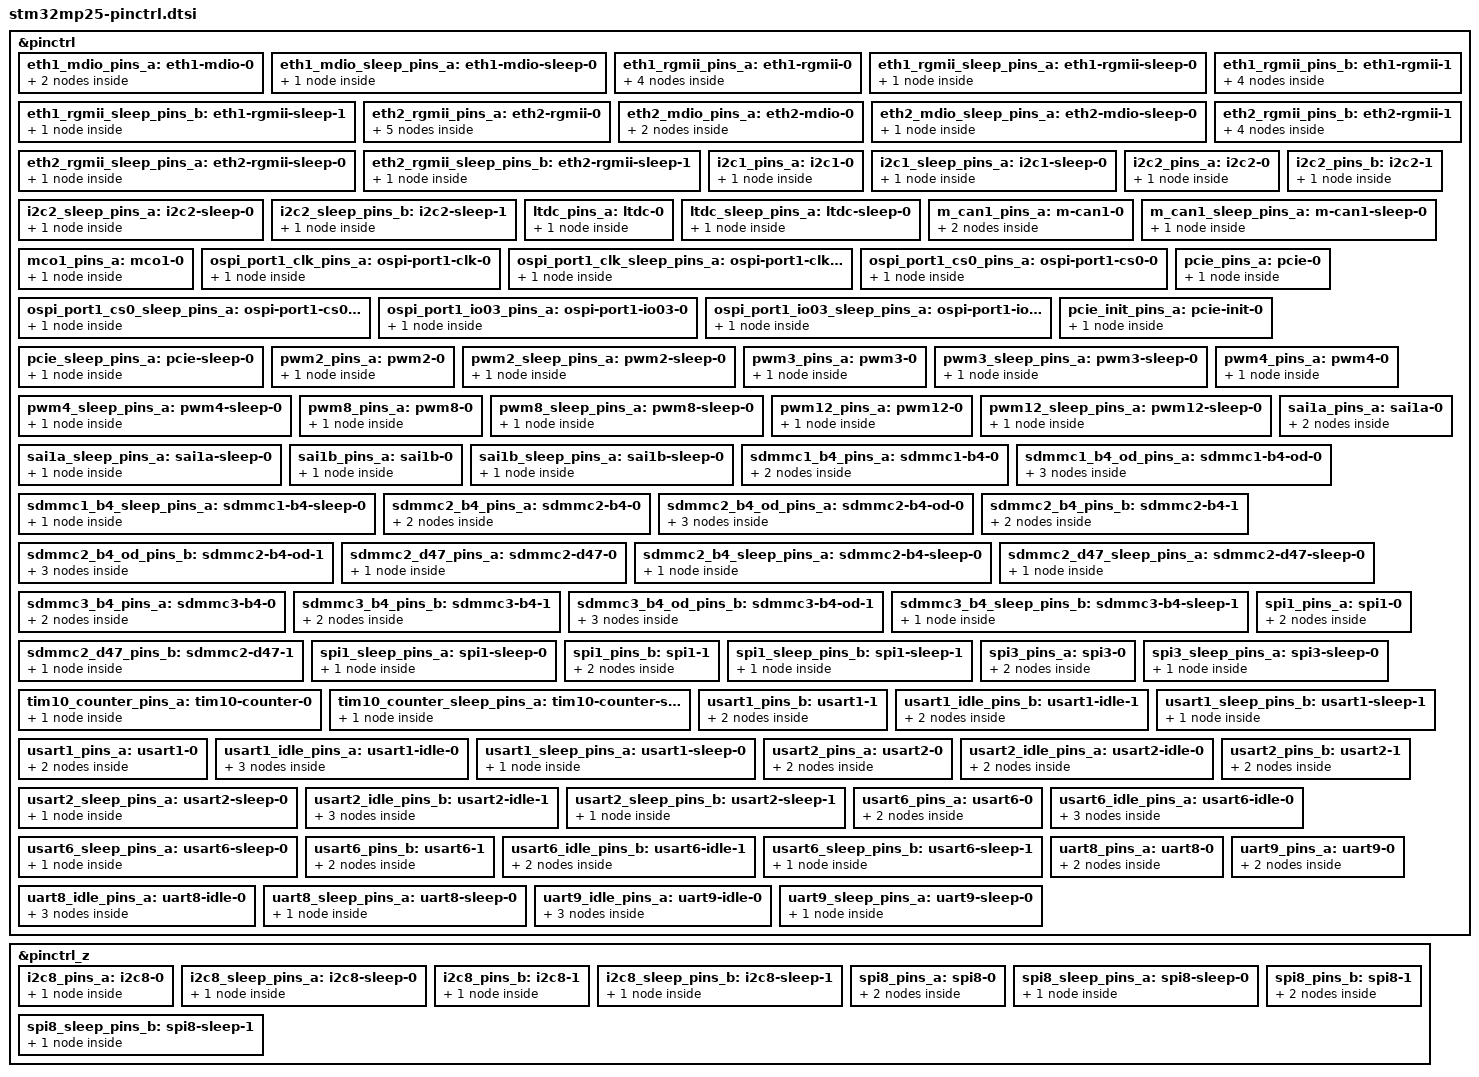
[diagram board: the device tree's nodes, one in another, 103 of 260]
// SPDX-License-Identifier: (GPL-2.0-or-later OR BSD-3-Clause)
/*
 * Copyright (C) STMicroelectronics 2023 - All Rights Reserved
 * Author: Alexandre Torgue <alexandre.torgue@foss.st.com> for STMicroelectronics.
 */
#include <dt-bindings/pinctrl/stm32-pinfunc.h>

&pinctrl {
	/omit-if-no-ref/
	eth1_mdio_pins_a: eth1-mdio-0 {
		pins1 {
			pinmux = <STM32_PINMUX('F', 0, AF10)>; /* ETH_MDC */
			bias-disable;
			drive-push-pull;
			slew-rate = <2>;
		};
		pins2 {
			pinmux = <STM32_PINMUX('F', 2, AF10)>; /* ETH_MDIO */
			bias-disable;
			drive-push-pull;
			slew-rate = <0>;
		};
	};

	/omit-if-no-ref/
	eth1_mdio_sleep_pins_a: eth1-mdio-sleep-0 {
		pins1 {
			pinmux = <STM32_PINMUX('F', 0, ANALOG)>, /* ETH_MDC */
				 <STM32_PINMUX('F', 2, ANALOG)>; /* ETH_MDIO */
		};
	};

	/omit-if-no-ref/
	eth1_rgmii_pins_a: eth1-rgmii-0 {
		pins1 {
			pinmux = <STM32_PINMUX('A', 15, AF10)>, /* ETH_RGMII_TXD0 */
				 <STM32_PINMUX('C', 1, AF10)>, /* ETH_RGMII_TXD1 */
				 <STM32_PINMUX('H', 10, AF10)>, /* ETH_RGMII_TXD2 */
				 <STM32_PINMUX('H', 11, AF10)>, /* ETH_RGMII_TXD3 */
				 <STM32_PINMUX('A', 13, AF10)>; /* ETH_RGMII_TX_CTL */
			bias-disable;
			drive-push-pull;
			slew-rate = <3>;
			st,io-sync = "data on both edges";
		};
		pins2 {
			pinmux = <STM32_PINMUX('H', 9, AF10)>, /* ETH_RGMII_CLK125 */
				 <STM32_PINMUX('C', 0, AF12)>; /* ETH_RGMII_GTX_CLK */
			bias-disable;
			drive-push-pull;
			slew-rate = <3>;
		};
		pins3 {
			pinmux = <STM32_PINMUX('F', 1, AF10)>, /* ETH_RGMII_RXD0 */
				 <STM32_PINMUX('C', 2, AF10)>, /* ETH_RGMII_RXD1 */
				 <STM32_PINMUX('H', 12, AF10)>, /* ETH_RGMII_RXD2 */
				 <STM32_PINMUX('H', 13, AF10)>, /* ETH_RGMII_RXD3 */
				 <STM32_PINMUX('A', 11, AF10)>; /* ETH_RGMII_RX_CTL */
			bias-disable;
			st,io-sync = "data on both edges";
		};
		pins4 {
			pinmux = <STM32_PINMUX('A', 14, AF10)>; /* ETH_RGMII_RX_CLK */
			bias-disable;
		};
	};

	/omit-if-no-ref/
	eth1_rgmii_sleep_pins_a: eth1-rgmii-sleep-0 {
		pins {
			pinmux = <STM32_PINMUX('A', 15, ANALOG)>, /* ETH_RGMII_TXD0 */
				 <STM32_PINMUX('C', 1, ANALOG)>, /* ETH_RGMII_TXD1 */
				 <STM32_PINMUX('H', 10, ANALOG)>, /* ETH_RGMII_TXD2 */
				 <STM32_PINMUX('H', 11, ANALOG)>, /* ETH_RGMII_TXD3 */
				 <STM32_PINMUX('A', 13, ANALOG)>, /* ETH_RGMII_TX_CTL */
				 <STM32_PINMUX('H', 9, ANALOG)>, /* ETH_RGMII_CLK125 */
				 <STM32_PINMUX('C', 0, ANALOG)>, /* ETH_RGMII_GTX_CLK */
				 <STM32_PINMUX('F', 1, ANALOG)>, /* ETH_RGMII_RXD0 */
				 <STM32_PINMUX('C', 2, ANALOG)>, /* ETH_RGMII_RXD1 */
				 <STM32_PINMUX('H', 12, ANALOG)>, /* ETH_RGMII_RXD2 */
				 <STM32_PINMUX('H', 13, ANALOG)>, /* ETH_RGMII_RXD3 */
				 <STM32_PINMUX('A', 11, ANALOG)>, /* ETH_RGMII_RX_CTL */
				 <STM32_PINMUX('A', 14, ANALOG)>; /* ETH_RGMII_RX_CLK */
		};
	};

	/omit-if-no-ref/
	eth1_rgmii_pins_b: eth1-rgmii-1 {
		pins1 {
			pinmux = <STM32_PINMUX('A', 15, AF10)>, /* ETH_RGMII_TXD0 */
				 <STM32_PINMUX('C', 1, AF10)>, /* ETH_RGMII_TXD1 */
				 <STM32_PINMUX('H', 10, AF10)>, /* ETH_RGMII_TXD2 */
				 <STM32_PINMUX('H', 11, AF10)>, /* ETH_RGMII_TXD3 */
				 <STM32_PINMUX('A', 13, AF10)>; /* ETH_RGMII_TX_CTL */
			bias-disable;
			drive-push-pull;
			slew-rate = <3>;
			st,io-sync = "data on both edges";
		};
		pins2 {
			pinmux = <STM32_PINMUX('H', 9, AF10)>, /* ETH_RGMII_CLK125 */
				 <STM32_PINMUX('C', 0, AF12)>, /* ETH_RGMII_GTX_CLK */
				 <STM32_PINMUX('A', 9, AF10)>, /* ETH_MDC */
				 <STM32_PINMUX('A', 10, AF10)>; /* ETH_MDIO */
			bias-disable;
			drive-push-pull;
			slew-rate = <3>;
		};
		pins3 {
			pinmux = <STM32_PINMUX('F', 1, AF10)>, /* ETH_RGMII_RXD0 */
				 <STM32_PINMUX('C', 2, AF10)>, /* ETH_RGMII_RXD1 */
				 <STM32_PINMUX('H', 12, AF10)>, /* ETH_RGMII_RXD2 */
				 <STM32_PINMUX('H', 13, AF10)>, /* ETH_RGMII_RXD3 */
				 <STM32_PINMUX('A', 11, AF10)>; /* ETH_RGMII_RX_CTL */
			bias-disable;
			st,io-sync = "data on both edges";
		};
		pins4 {
			pinmux = <STM32_PINMUX('A', 14, AF10)>; /* ETH_RGMII_RX_CLK */
			bias-disable;
		};
	};

	/omit-if-no-ref/
	eth1_rgmii_sleep_pins_b: eth1-rgmii-sleep-1 {
		pins {
			pinmux = <STM32_PINMUX('A', 15, ANALOG)>, /* ETH_RGMII_TXD0 */
				 <STM32_PINMUX('C', 1, ANALOG)>, /* ETH_RGMII_TXD1 */
				 <STM32_PINMUX('H', 10, ANALOG)>, /* ETH_RGMII_TXD2 */
				 <STM32_PINMUX('H', 11, ANALOG)>, /* ETH_RGMII_TXD3 */
				 <STM32_PINMUX('A', 13, ANALOG)>, /* ETH_RGMII_TX_CTL */
				 <STM32_PINMUX('H', 9, ANALOG)>, /* ETH_RGMII_CLK125 */
				 <STM32_PINMUX('C', 0, ANALOG)>, /* ETH_RGMII_GTX_CLK */
				 <STM32_PINMUX('A', 9, ANALOG)>, /* ETH_MDC */
				 <STM32_PINMUX('A', 10, ANALOG)>, /* ETH_MDIO */
				 <STM32_PINMUX('F', 1, ANALOG)>, /* ETH_RGMII_RXD0 */
				 <STM32_PINMUX('C', 2, ANALOG)>, /* ETH_RGMII_RXD1 */
				 <STM32_PINMUX('H', 12, ANALOG)>, /* ETH_RGMII_RXD2 */
				 <STM32_PINMUX('H', 13, ANALOG)>, /* ETH_RGMII_RXD3 */
				 <STM32_PINMUX('A', 11, ANALOG)>, /* ETH_RGMII_RX_CTL */
				 <STM32_PINMUX('A', 14, AF10)>; /* ETH_RGMII_RX_CLK */
		};
	};

	/omit-if-no-ref/
	eth2_rgmii_pins_a: eth2-rgmii-0 {
		pins1 {
			pinmux = <STM32_PINMUX('C', 7, AF10)>, /* ETH_RGMII_TXD0 */
				 <STM32_PINMUX('C', 8, AF10)>, /* ETH_RGMII_TXD1 */
				 <STM32_PINMUX('C', 9, AF10)>, /* ETH_RGMII_TXD2 */
				 <STM32_PINMUX('C', 10, AF10)>, /* ETH_RGMII_TXD3 */
				 <STM32_PINMUX('C', 4, AF10)>; /* ETH_RGMII_TX_CTL */
			bias-disable;
			drive-push-pull;
			slew-rate = <3>;
			st,io-sync = "data on both edges";
		};
		pins2 {
			pinmux = <STM32_PINMUX('F', 8, AF10)>, /* ETH_RGMII_CLK125 */
				 <STM32_PINMUX('F', 7, AF10)>, /* ETH_RGMII_GTX_CLK */
				 <STM32_PINMUX('C', 6, AF10)>; /* ETH_MDC */
			bias-disable;
			drive-push-pull;
			slew-rate = <3>;
		};
		pins3 {
			pinmux = <STM32_PINMUX('C', 5, AF10)>; /* ETH_MDIO */
			bias-disable;
			drive-push-pull;
			slew-rate = <0>;
		};
		pins4 {
			pinmux = <STM32_PINMUX('G', 0, AF10)>, /* ETH_RGMII_RXD0 */
				 <STM32_PINMUX('C', 12, AF10)>, /* ETH_RGMII_RXD1 */
				 <STM32_PINMUX('F', 9, AF10)>, /* ETH_RGMII_RXD2 */
				 <STM32_PINMUX('C', 11, AF10)>, /* ETH_RGMII_RXD3 */
				 <STM32_PINMUX('C', 3, AF10)>; /* ETH_RGMII_RX_CTL */
			bias-disable;
			st,io-sync = "data on both edges";
		};
		pins5 {
			pinmux = <STM32_PINMUX('F', 6, AF10)>; /* ETH_RGMII_RX_CLK */
			bias-disable;
		};
	};

	/omit-if-no-ref/
	eth2_mdio_pins_a: eth2-mdio-0 {
		pins1 {
			pinmux = <STM32_PINMUX('G', 4, AF11)>; /* ETH_MDC */
			bias-disable;
			drive-push-pull;
			slew-rate = <3>;
		};
		pins2 {
			pinmux = <STM32_PINMUX('C', 5, AF10)>; /* ETH_MDIO */
			bias-disable;
			drive-push-pull;
			slew-rate = <0>;
		};
	};

	/omit-if-no-ref/
	eth2_mdio_sleep_pins_a: eth2-mdio-sleep-0 {
		pins {
			pinmux = <STM32_PINMUX('G', 4, ANALOG)>, /* ETH_MDC */
				 <STM32_PINMUX('C', 5, ANALOG)>; /* ETH_MDIO */
		};
	};

	/omit-if-no-ref/
	eth2_rgmii_sleep_pins_a: eth2-rgmii-sleep-0 {
		pins {
			pinmux = <STM32_PINMUX('C', 7, ANALOG)>, /* ETH_RGMII_TXD0 */
				 <STM32_PINMUX('C', 8, ANALOG)>, /* ETH_RGMII_TXD1 */
				 <STM32_PINMUX('C', 9, ANALOG)>, /* ETH_RGMII_TXD2 */
				 <STM32_PINMUX('C', 10, ANALOG)>, /* ETH_RGMII_TXD3 */
				 <STM32_PINMUX('C', 4, ANALOG)>, /* ETH_RGMII_TX_CTL */
				 <STM32_PINMUX('F', 8, ANALOG)>, /* ETH_RGMII_CLK125 */
				 <STM32_PINMUX('F', 7, ANALOG)>, /* ETH_RGMII_GTX_CLK */
				 <STM32_PINMUX('C', 6, ANALOG)>, /* ETH_MDC */
				 <STM32_PINMUX('C', 5, ANALOG)>, /* ETH_MDIO */
				 <STM32_PINMUX('G', 0, ANALOG)>, /* ETH_RGMII_RXD0 */
				 <STM32_PINMUX('C', 12, ANALOG)>, /* ETH_RGMII_RXD1 */
				 <STM32_PINMUX('F', 9, ANALOG)>, /* ETH_RGMII_RXD2 */
				 <STM32_PINMUX('C', 11, ANALOG)>, /* ETH_RGMII_RXD3 */
				 <STM32_PINMUX('C', 3, ANALOG)>, /* ETH_RGMII_RX_CTL */
				 <STM32_PINMUX('F', 6, ANALOG)>; /* ETH_RGMII_RX_CLK */
		};
	};

	/omit-if-no-ref/
	eth2_rgmii_pins_b: eth2-rgmii-1 {
		pins1 {
			pinmux = <STM32_PINMUX('C', 7, AF10)>, /* ETH_RGMII_TXD0 */
				 <STM32_PINMUX('C', 8, AF10)>, /* ETH_RGMII_TXD1 */
				 <STM32_PINMUX('C', 9, AF10)>, /* ETH_RGMII_TXD2 */
				 <STM32_PINMUX('C', 10, AF10)>, /* ETH_RGMII_TXD3 */
				 <STM32_PINMUX('C', 4, AF10)>; /* ETH_RGMII_TX_CTL */
			bias-disable;
			drive-push-pull;
			slew-rate = <3>;
			st,io-sync = "data on both edges";
		};
		pins2 {
			pinmux = <STM32_PINMUX('F', 8, AF10)>, /* ETH_RGMII_CLK125 */
				 <STM32_PINMUX('F', 7, AF10)>; /* ETH_RGMII_GTX_CLK */
			bias-disable;
			drive-push-pull;
			slew-rate = <3>;
		};
		pins3 {
			pinmux = <STM32_PINMUX('G', 0, AF10)>, /* ETH_RGMII_RXD0 */
				 <STM32_PINMUX('C', 12, AF10)>, /* ETH_RGMII_RXD1 */
				 <STM32_PINMUX('F', 9, AF10)>, /* ETH_RGMII_RXD2 */
				 <STM32_PINMUX('C', 11, AF10)>, /* ETH_RGMII_RXD3 */
				 <STM32_PINMUX('C', 3, AF10)>; /* ETH_RGMII_RX_CTL */
			bias-disable;
			st,io-sync = "data on both edges";
		};
		pins4 {
			pinmux = <STM32_PINMUX('F', 6, AF10)>; /* ETH_RGMII_RX_CLK */
			bias-disable;
		};
	};

	/omit-if-no-ref/
	eth2_rgmii_sleep_pins_b: eth2-rgmii-sleep-1 {
		pins {
			pinmux = <STM32_PINMUX('C', 7, ANALOG)>, /* ETH_RGMII_TXD0 */
				 <STM32_PINMUX('C', 8, ANALOG)>, /* ETH_RGMII_TXD1 */
				 <STM32_PINMUX('C', 9, ANALOG)>, /* ETH_RGMII_TXD2 */
				 <STM32_PINMUX('C', 10, ANALOG)>, /* ETH_RGMII_TXD3 */
				 <STM32_PINMUX('C', 4, ANALOG)>, /* ETH_RGMII_TX_CTL */
				 <STM32_PINMUX('F', 8, ANALOG)>, /* ETH_RGMII_CLK125 */
				 <STM32_PINMUX('F', 7, ANALOG)>, /* ETH_RGMII_GTX_CLK */
				 <STM32_PINMUX('G', 0, ANALOG)>, /* ETH_RGMII_RXD0 */
				 <STM32_PINMUX('C', 12, ANALOG)>, /* ETH_RGMII_RXD1 */
				 <STM32_PINMUX('F', 9, ANALOG)>, /* ETH_RGMII_RXD2 */
				 <STM32_PINMUX('C', 11, ANALOG)>, /* ETH_RGMII_RXD3 */
				 <STM32_PINMUX('C', 3, ANALOG)>, /* ETH_RGMII_RX_CTL */
				 <STM32_PINMUX('F', 6, ANALOG)>; /* ETH_RGMII_RX_CLK */
		};
	};

	/omit-if-no-ref/
	i2c1_pins_a: i2c1-0 {
		pins {
			pinmux = <STM32_PINMUX('G', 13, AF9)>, /* I2C1_SCL */
				 <STM32_PINMUX('A', 2, AF10)>; /* I2C1_SDA */
			bias-disable;
			drive-open-drain;
			slew-rate = <0>;
		};
	};

	/omit-if-no-ref/
	i2c1_sleep_pins_a: i2c1-sleep-0 {
		pins {
			pinmux = <STM32_PINMUX('G', 13, ANALOG)>, /* I2C1_SCL */
				 <STM32_PINMUX('A', 2, ANALOG)>; /* I2C1_SDA */
		};
	};

	/omit-if-no-ref/
	i2c2_pins_a: i2c2-0 {
		pins {
			pinmux = <STM32_PINMUX('B', 5, AF9)>, /* I2C2_SCL */
				 <STM32_PINMUX('B', 4, AF9)>; /* I2C2_SDA */
			bias-disable;
			drive-open-drain;
			slew-rate = <0>;
		};
	};

	/omit-if-no-ref/
	i2c2_sleep_pins_a: i2c2-sleep-0 {
		pins {
			pinmux = <STM32_PINMUX('B', 5, ANALOG)>, /* I2C2_SCL */
				 <STM32_PINMUX('B', 4, ANALOG)>; /* I2C2_SDA */
		};
	};

	/omit-if-no-ref/
	i2c2_pins_b: i2c2-1 {
		pins {
			pinmux = <STM32_PINMUX('F', 2, AF9)>, /* I2C2_SCL */
				 <STM32_PINMUX('F', 0, AF9)>; /* I2C2_SDA */
			bias-disable;
			drive-open-drain;
			slew-rate = <0>;
		};
	};

	/omit-if-no-ref/
	i2c2_sleep_pins_b: i2c2-sleep-1 {
		pins {
			pinmux = <STM32_PINMUX('F', 2, ANALOG)>, /* I2C2_SCL */
				 <STM32_PINMUX('F', 0, ANALOG)>; /* I2C2_SDA */
		};
	};

	/omit-if-no-ref/
	ltdc_pins_a: ltdc-0 {
		pins {
			pinmux = <STM32_PINMUX('C',  6, AF14)>, /* LCD_CLK */
				 <STM32_PINMUX('G',  2, AF13)>, /* LCD_HSYNC */
				 <STM32_PINMUX('G',  1, AF13)>, /* LCD_VSYNC */
				 <STM32_PINMUX('C',  5, AF14)>, /* LCD_DE */
				 <STM32_PINMUX('H',  4, AF10)>, /* LCD_R0 */
				 <STM32_PINMUX('F',  7, AF13)>, /* LCD_R1 */
				 <STM32_PINMUX('C', 11, AF13)>, /* LCD_R2 */
				 <STM32_PINMUX('A',  1, AF11)>, /* LCD_R3 */
				 <STM32_PINMUX('B', 15, AF13)>, /* LCD_R4 */
				 <STM32_PINMUX('G',  3, AF13)>, /* LCD_R5 */
				 <STM32_PINMUX('A', 10, AF12)>, /* LCD_R6 */
				 <STM32_PINMUX('G',  7, AF13)>, /* LCD_R7 */
				 <STM32_PINMUX('F',  8, AF13)>, /* LCD_G0 */
				 <STM32_PINMUX('H',  5, AF10)>, /* LCD_G1 */
				 <STM32_PINMUX('C',  9, AF13)>, /* LCD_G2 */
				 <STM32_PINMUX('C', 10, AF13)>, /* LCD_G3 */
				 <STM32_PINMUX('A',  6, AF10)>, /* LCD_G4 */
				 <STM32_PINMUX('G', 11, AF13)>, /* LCD_G5 */
				 <STM32_PINMUX('G', 12, AF13)>, /* LCD_G6 */
				 <STM32_PINMUX('A',  9, AF12)>, /* LCD_G7 */
				 <STM32_PINMUX('F',  6, AF13)>, /* LCD_B0 */
				 <STM32_PINMUX('A',  3, AF11)>, /* LCD_B1 */
				 <STM32_PINMUX('G', 15, AF13)>, /* LCD_B2 */
				 <STM32_PINMUX('I',  0, AF13)>, /* LCD_B3 */
				 <STM32_PINMUX('I',  1, AF13)>, /* LCD_B4 */
				 <STM32_PINMUX('A',  7, AF10)>, /* LCD_B5 */
				 <STM32_PINMUX('F',  5, AF13)>, /* LCD_B6 */
				 <STM32_PINMUX('I',  4, AF13)>; /* LCD_B7 */
			bias-disable;
			drive-push-pull;
			slew-rate = <1>;
		};
	};

	/omit-if-no-ref/
	ltdc_sleep_pins_a: ltdc-sleep-0 {
		pins {
			pinmux = <STM32_PINMUX('C',  6, ANALOG)>, /* LCD_CLK */
				 <STM32_PINMUX('G',  2, ANALOG)>, /* LCD_HSYNC */
				 <STM32_PINMUX('G',  1, ANALOG)>, /* LCD_VSYNC */
				 <STM32_PINMUX('C',  5, ANALOG)>, /* LCD_DE */
				 <STM32_PINMUX('H',  4, ANALOG)>, /* LCD_R0 */
				 <STM32_PINMUX('F',  7, ANALOG)>, /* LCD_R1 */
				 <STM32_PINMUX('C', 11, ANALOG)>, /* LCD_R2 */
				 <STM32_PINMUX('A',  1, ANALOG)>, /* LCD_R3 */
				 <STM32_PINMUX('B', 15, ANALOG)>, /* LCD_R4 */
				 <STM32_PINMUX('G',  3, ANALOG)>, /* LCD_R5 */
				 <STM32_PINMUX('A', 10, ANALOG)>, /* LCD_R6 */
				 <STM32_PINMUX('G',  7, ANALOG)>, /* LCD_R7 */
				 <STM32_PINMUX('F',  8, ANALOG)>, /* LCD_G0 */
				 <STM32_PINMUX('H',  5, ANALOG)>, /* LCD_G1 */
				 <STM32_PINMUX('C',  9, ANALOG)>, /* LCD_G2 */
				 <STM32_PINMUX('C', 10, ANALOG)>, /* LCD_G3 */
				 <STM32_PINMUX('A',  6, ANALOG)>, /* LCD_G4 */
				 <STM32_PINMUX('G', 11, ANALOG)>, /* LCD_G5 */
				 <STM32_PINMUX('G', 12, ANALOG)>, /* LCD_G6 */
				 <STM32_PINMUX('A',  9, ANALOG)>, /* LCD_G7 */
				 <STM32_PINMUX('F',  6, ANALOG)>, /* LCD_B0 */
				 <STM32_PINMUX('A',  3, ANALOG)>, /* LCD_B1 */
				 <STM32_PINMUX('G', 15, ANALOG)>, /* LCD_B2 */
				 <STM32_PINMUX('I',  0, ANALOG)>, /* LCD_B3 */
				 <STM32_PINMUX('I',  1, ANALOG)>, /* LCD_B4 */
				 <STM32_PINMUX('A',  7, ANALOG)>, /* LCD_B5 */
				 <STM32_PINMUX('F',  5, ANALOG)>, /* LCD_B6 */
				 <STM32_PINMUX('I',  4, ANALOG)>; /* LCD_B7 */
		};
	};

	/omit-if-no-ref/
	m_can1_pins_a: m-can1-0 {
		pins1 {
			pinmux = <STM32_PINMUX('B', 9, AF7)>; /* CAN1_TX */
			slew-rate = <1>;
			drive-push-pull;
			bias-disable;
		};
		pins2 {
			pinmux = <STM32_PINMUX('B', 11, AF7)>; /* CAN1_RX */
			bias-disable;
		};
	};

	/omit-if-no-ref/
	m_can1_sleep_pins_a: m-can1-sleep-0 {
		pins {
			pinmux = <STM32_PINMUX('B', 9, ANALOG)>, /* CAN1_TX */
				 <STM32_PINMUX('B', 11, ANALOG)>; /* CAN1_RX */
		};
	};

	/omit-if-no-ref/
	mco1_pins_a: mco1-0 {
		pins {
			pinmux = <STM32_PINMUX('I', 6, AF1)>; /* MCO1 */
			bias-disable;
			drive-push-pull;
			slew-rate = <2>;
		};
	};

	/omit-if-no-ref/
	ospi_port1_clk_pins_a: ospi-port1-clk-0 {
		pins {
			pinmux = <STM32_PINMUX('D', 0, AF10)>; /* OSPI1_CLK */
			bias-disable;
			drive-push-pull;
			slew-rate = <2>;
		};
	};

	/omit-if-no-ref/
	ospi_port1_clk_sleep_pins_a: ospi-port1-clk-sleep-0 {
		pins {
			pinmux = <STM32_PINMUX('D', 0, ANALOG)>; /* OSPI1_CLK */
		};
	};

	/omit-if-no-ref/
	ospi_port1_cs0_pins_a: ospi-port1-cs0-0 {
		pins {
			pinmux = <STM32_PINMUX('D', 3, AF10)>; /* OSPI_NCS0 */
			bias-pull-up;
			drive-push-pull;
			slew-rate = <0>;
		};
	};

	/omit-if-no-ref/
	ospi_port1_cs0_sleep_pins_a: ospi-port1-cs0-sleep-0 {
		pins {
			pinmux = <STM32_PINMUX('D', 3, ANALOG)>; /* OSPI_NCS0 */
		};
	};

	/omit-if-no-ref/
	ospi_port1_io03_pins_a: ospi-port1-io03-0 {
		pins {
			pinmux = <STM32_PINMUX('D', 4, AF10)>, /* OSPI_IO0 */
				 <STM32_PINMUX('D', 5, AF10)>, /* OSPI_IO1 */
				 <STM32_PINMUX('D', 6, AF10)>, /* OSPI_IO2 */
				 <STM32_PINMUX('D', 7, AF10)>; /* OSPI_IO3 */
			bias-disable;
			drive-push-pull;
			slew-rate = <0>;
		};
	};

	/omit-if-no-ref/
	ospi_port1_io03_sleep_pins_a: ospi-port1-io03-sleep-0 {
		pins {
			pinmux = <STM32_PINMUX('D', 4, ANALOG)>, /* OSPI_IO0 */
				 <STM32_PINMUX('D', 5, ANALOG)>, /* OSPI_IO1 */
				 <STM32_PINMUX('D', 6, ANALOG)>, /* OSPI_IO2 */
				 <STM32_PINMUX('D', 7, ANALOG)>; /* OSPI_IO3 */
		};
	};

	/omit-if-no-ref/
	pcie_pins_a: pcie-0 {
		pins {
			pinmux = <STM32_PINMUX('J', 0, AF4)>;
			bias-disable;
		};
	};

	/omit-if-no-ref/
	pcie_init_pins_a: pcie-init-0 {
		pins {
			pinmux = <STM32_PINMUX('J', 0, GPIO)>;
			output-low;
		};
	};

	/omit-if-no-ref/
	pcie_sleep_pins_a: pcie-sleep-0 {
		pins {
			pinmux = <STM32_PINMUX('J', 0, ANALOG)>;
		};
	};

	/omit-if-no-ref/
	pwm2_pins_a: pwm2-0 {
		pins {
			pinmux = <STM32_PINMUX('I', 7, AF7)>; /* TIM2_CH1 */
			bias-pull-down;
			drive-push-pull;
			slew-rate = <0>;
		};
	};

	/omit-if-no-ref/
	pwm2_sleep_pins_a: pwm2-sleep-0 {
		pins {
			pinmux = <STM32_PINMUX('I', 7, ANALOG)>; /* TIM2_CH1 */
		};
	};

	/omit-if-no-ref/
	pwm3_pins_a: pwm3-0 {
		pins {
			pinmux = <STM32_PINMUX('B', 15, AF7)>; /* TIM3_CH2 */
			bias-pull-down;
			drive-push-pull;
			slew-rate = <0>;
		};
	};

	/omit-if-no-ref/
	pwm3_sleep_pins_a: pwm3-sleep-0 {
		pins {
			pinmux = <STM32_PINMUX('B', 15, ANALOG)>; /* TIM3_CH2 */
		};
	};

	/omit-if-no-ref/
	pwm4_pins_a: pwm4-0 {
		pins {
			pinmux = <STM32_PINMUX('A', 12, AF7)>; /* TIM4_CH1 */
			bias-pull-down;
			drive-push-pull;
			slew-rate = <0>;
		};
	};

	/omit-if-no-ref/
	pwm4_sleep_pins_a: pwm4-sleep-0 {
		pins {
			pinmux = <STM32_PINMUX('A', 12, ANALOG)>; /* TIM4_CH1 */
		};
	};

	/omit-if-no-ref/
	pwm8_pins_a: pwm8-0 {
		pins {
			pinmux = <STM32_PINMUX('J', 5, AF8)>, /* TIM8_CH1 */
				 <STM32_PINMUX('J', 4, AF8)>; /* TIM8_CH4 */
			bias-pull-down;
			drive-push-pull;
			slew-rate = <0>;
		};
	};

	/omit-if-no-ref/
	pwm8_sleep_pins_a: pwm8-sleep-0 {
		pins {
			pinmux = <STM32_PINMUX('J', 5, ANALOG)>, /* TIM8_CH1 */
				 <STM32_PINMUX('J', 4, ANALOG)>; /* TIM8_CH4 */
		};
	};

	/omit-if-no-ref/
	pwm12_pins_a: pwm12-0 {
		pins {
			pinmux = <STM32_PINMUX('B', 11, AF9)>; /* TIM12_CH2 */
			bias-pull-down;
			drive-push-pull;
			slew-rate = <0>;
		};
	};

	/omit-if-no-ref/
	pwm12_sleep_pins_a: pwm12-sleep-0 {
		pins {
			pinmux = <STM32_PINMUX('B', 11, ANALOG)>; /* TIM12_CH2 */
		};
	};

	/omit-if-no-ref/
	sai1a_pins_a: sai1a-0 {
		pins1 {
			pinmux = <STM32_PINMUX('D', 9, AF3)>, /* SAI1_SD_A */
				 <STM32_PINMUX('D', 8, AF3)>, /* SAI1_FS_A */
				 <STM32_PINMUX('D', 10, AF3)>; /* SAI1_SCK_A */
			bias-disable;
			drive-push-pull;
			slew-rate = <1>;
		};
		pins2 {
			pinmux = <STM32_PINMUX('D', 11, AF3)>; /* SAI1_MCLK_A */
			bias-disable;
			drive-push-pull;
			slew-rate = <2>;
		};
	};

	/omit-if-no-ref/
	sai1a_sleep_pins_a: sai1a-sleep-0 {
		pins {
			pinmux = <STM32_PINMUX('D', 9, ANALOG)>, /* SAI1_SD_A */
				 <STM32_PINMUX('D', 8, ANALOG)>, /* SAI1_FS_A */
				 <STM32_PINMUX('D', 10, ANALOG)>, /* SAI1_SCK_A */
				 <STM32_PINMUX('D', 11, ANALOG)>; /* SAI1_MCLK_A */
		};
	};

	/omit-if-no-ref/
	sai1b_pins_a: sai1b-0 {
		pins {
			pinmux = <STM32_PINMUX('D', 4, AF4)>; /* SAI1_SD_B */
			bias-disable;
			drive-push-pull;
			slew-rate = <0>;
		};
	};

	/omit-if-no-ref/
	sai1b_sleep_pins_a: sai1b-sleep-0 {
		pins {
			pinmux = <STM32_PINMUX('D', 4, ANALOG)>; /* SAI1_SD_B */
		};
	};

	/omit-if-no-ref/
	sdmmc1_b4_pins_a: sdmmc1-b4-0 {
		pins1 {
			pinmux = <STM32_PINMUX('E', 4, AF10)>, /* SDMMC1_D0 */
				 <STM32_PINMUX('E', 5, AF10)>, /* SDMMC1_D1 */
				 <STM32_PINMUX('E', 0, AF10)>, /* SDMMC1_D2 */
				 <STM32_PINMUX('E', 1, AF10)>, /* SDMMC1_D3 */
				 <STM32_PINMUX('E', 2, AF10)>; /* SDMMC1_CMD */
			slew-rate = <2>;
			drive-push-pull;
			bias-disable;
		};
		pins2 {
			pinmux = <STM32_PINMUX('E', 3, AF10)>; /* SDMMC1_CK */
			slew-rate = <3>;
			drive-push-pull;
			bias-disable;
		};
	};

	/omit-if-no-ref/
	sdmmc1_b4_od_pins_a: sdmmc1-b4-od-0 {
		pins1 {
			pinmux = <STM32_PINMUX('E', 4, AF10)>, /* SDMMC1_D0 */
				 <STM32_PINMUX('E', 5, AF10)>, /* SDMMC1_D1 */
				 <STM32_PINMUX('E', 0, AF10)>, /* SDMMC1_D2 */
				 <STM32_PINMUX('E', 1, AF10)>; /* SDMMC1_D3 */
			slew-rate = <2>;
			drive-push-pull;
			bias-disable;
		};
		pins2 {
			pinmux = <STM32_PINMUX('E', 3, AF10)>; /* SDMMC1_CK */
			slew-rate = <3>;
			drive-push-pull;
			bias-disable;
		};
		pins3 {
			pinmux = <STM32_PINMUX('E', 2, AF10)>; /* SDMMC1_CMD */
			slew-rate = <2>;
			drive-open-drain;
			bias-disable;
		};
	};

	/omit-if-no-ref/
	sdmmc1_b4_sleep_pins_a: sdmmc1-b4-sleep-0 {
		pins {
			pinmux = <STM32_PINMUX('E', 4, ANALOG)>, /* SDMMC1_D0 */
				 <STM32_PINMUX('E', 5, ANALOG)>, /* SDMMC1_D1 */
				 <STM32_PINMUX('E', 0, ANALOG)>, /* SDMMC1_D2 */
				 <STM32_PINMUX('E', 1, ANALOG)>, /* SDMMC1_D3 */
				 <STM32_PINMUX('E', 3, ANALOG)>, /* SDMMC1_CK */
				 <STM32_PINMUX('E', 2, ANALOG)>; /* SDMMC1_CMD */
		};
	};

	/omit-if-no-ref/
	sdmmc2_b4_pins_a: sdmmc2-b4-0 {
		pins1 {
			pinmux = <STM32_PINMUX('E', 13, AF12)>, /* SDMMC2_D0 */
				 <STM32_PINMUX('E', 11, AF12)>, /* SDMMC2_D1 */
				 <STM32_PINMUX('E', 8, AF12)>, /* SDMMC2_D2 */
				 <STM32_PINMUX('E', 12, AF12)>, /* SDMMC2_D3 */
				 <STM32_PINMUX('E', 15, AF12)>; /* SDMMC2_CMD */
			slew-rate = <1>;
			drive-push-pull;
			bias-pull-up;
		};
		pins2 {
			pinmux = <STM32_PINMUX('E', 14, AF12)>; /* SDMMC2_CK */
			slew-rate = <2>;
			drive-push-pull;
			bias-disable;
		};
	};

	/omit-if-no-ref/
	sdmmc2_b4_od_pins_a: sdmmc2-b4-od-0 {
		pins1 {
			pinmux = <STM32_PINMUX('E', 13, AF12)>, /* SDMMC2_D0 */
				 <STM32_PINMUX('E', 11, AF12)>, /* SDMMC2_D1 */
				 <STM32_PINMUX('E', 8, AF12)>, /* SDMMC2_D2 */
				 <STM32_PINMUX('E', 12, AF12)>; /* SDMMC2_D3 */
			slew-rate = <1>;
			drive-push-pull;
			bias-pull-up;
		};
		pins2 {
			pinmux = <STM32_PINMUX('E', 14, AF12)>; /* SDMMC2_CK */
			slew-rate = <2>;
			drive-push-pull;
			bias-disable;
		};
		pins3 {
			pinmux = <STM32_PINMUX('E', 15, AF12)>; /* SDMMC2_CMD */
			slew-rate = <1>;
			drive-open-drain;
			bias-pull-up;
		};
	};

	/omit-if-no-ref/
	sdmmc2_b4_pins_b: sdmmc2-b4-1 {
		pins1 {
			pinmux = <STM32_PINMUX('E', 13, AF12)>, /* SDMMC2_D0 */
				 <STM32_PINMUX('E', 11, AF12)>, /* SDMMC2_D1 */
				 <STM32_PINMUX('E', 8, AF12)>, /* SDMMC2_D2 */
				 <STM32_PINMUX('E', 12, AF12)>, /* SDMMC2_D3 */
				 <STM32_PINMUX('E', 15, AF12)>; /* SDMMC2_CMD */
			slew-rate = <2>;
			drive-push-pull;
			bias-pull-up;
		};
		pins2 {
			pinmux = <STM32_PINMUX('E', 14, AF12)>; /* SDMMC2_CK */
			slew-rate = <3>;
			drive-push-pull;
			bias-disable;
		};
	};

	/omit-if-no-ref/
	sdmmc2_b4_od_pins_b: sdmmc2-b4-od-1 {
		pins1 {
			pinmux = <STM32_PINMUX('E', 13, AF12)>, /* SDMMC2_D0 */
				 <STM32_PINMUX('E', 11, AF12)>, /* SDMMC2_D1 */
				 <STM32_PINMUX('E', 8, AF12)>, /* SDMMC2_D2 */
				 <STM32_PINMUX('E', 12, AF12)>; /* SDMMC2_D3 */
			slew-rate = <2>;
			drive-push-pull;
			bias-pull-up;
		};
		pins2 {
			pinmux = <STM32_PINMUX('E', 14, AF12)>; /* SDMMC2_CK */
			slew-rate = <3>;
			drive-push-pull;
			bias-disable;
		};
		pins3 {
			pinmux = <STM32_PINMUX('E', 15, AF12)>; /* SDMMC2_CMD */
			slew-rate = <2>;
			drive-open-drain;
			bias-pull-up;
		};
	};

	/omit-if-no-ref/
	sdmmc2_d47_pins_a: sdmmc2-d47-0 {
		pins {
			pinmux = <STM32_PINMUX('E', 10, AF12)>, /* SDMMC2_D4 */
				 <STM32_PINMUX('E', 9, AF12)>, /* SDMMC2_D5 */
				 <STM32_PINMUX('E', 6, AF12)>, /* SDMMC2_D6 */
				 <STM32_PINMUX('E', 7, AF12)>; /* SDMMC2_D7 */
			slew-rate = <1>;
			drive-push-pull;
			bias-pull-up;
		};
	};

	/omit-if-no-ref/
	sdmmc2_b4_sleep_pins_a: sdmmc2-b4-sleep-0 {
		pins {
			pinmux = <STM32_PINMUX('E', 13, ANALOG)>, /* SDMMC2_D0 */
				 <STM32_PINMUX('E', 11, ANALOG)>, /* SDMMC2_D1 */
				 <STM32_PINMUX('E', 8, ANALOG)>, /* SDMMC2_D2 */
				 <STM32_PINMUX('E', 12, ANALOG)>, /* SDMMC2_D3 */
				 <STM32_PINMUX('E', 14, ANALOG)>, /* SDMMC2_CK */
				 <STM32_PINMUX('E', 15, ANALOG)>; /* SDMMC2_CMD */
		};
	};

	/omit-if-no-ref/
	sdmmc2_d47_sleep_pins_a: sdmmc2-d47-sleep-0 {
		pins {
			pinmux = <STM32_PINMUX('E', 10, ANALOG)>, /* SDMMC2_D4 */
				 <STM32_PINMUX('E', 9, ANALOG)>, /* SDMMC2_D5 */
				 <STM32_PINMUX('E', 6, ANALOG)>, /* SDMMC2_D6 */
				 <STM32_PINMUX('E', 7, ANALOG)>; /* SDMMC2_D7 */
		};
	};

	/omit-if-no-ref/
	sdmmc3_b4_pins_a: sdmmc3-b4-0 {
		pins1 {
			pinmux = <STM32_PINMUX('B', 14, AF10)>, /* SDMMC3_D0 */
				 <STM32_PINMUX('D', 13, AF10)>, /* SDMMC3_D1 */
				 <STM32_PINMUX('B', 12, AF10)>, /* SDMMC3_D2 */
				 <STM32_PINMUX('I', 11, AF10)>, /* SDMMC3_D3 */
				 <STM32_PINMUX('D', 12, AF10)>; /* SDMMC3_CMD */
			slew-rate = <0>;
			drive-push-pull;
			bias-pull-up;
		};
		pins2 {
			pinmux = <STM32_PINMUX('B', 13, AF10)>; /* SDMMC3_CK */
			slew-rate = <1>;
			drive-push-pull;
			bias-pull-up;
		};
	};

	/omit-if-no-ref/
	sdmmc3_b4_pins_b: sdmmc3-b4-1 {
		pins1 {
			pinmux = <STM32_PINMUX('B', 14, AF10)>, /* SDMMC3_D0 */
				 <STM32_PINMUX('D', 13, AF10)>, /* SDMMC3_D1 */
				 <STM32_PINMUX('B', 12, AF10)>, /* SDMMC3_D2 */
				 <STM32_PINMUX('D', 14, AF12)>, /* SDMMC3_D3 */
				 <STM32_PINMUX('D', 12, AF10)>; /* SDMMC3_CMD */
			slew-rate = <0>;
			drive-push-pull;
			bias-pull-up;
		};
		pins2 {
			pinmux = <STM32_PINMUX('B', 13, AF10)>; /* SDMMC3_CK */
			slew-rate = <1>;
			drive-push-pull;
			bias-pull-up;
		};
	};

	/omit-if-no-ref/
	sdmmc3_b4_od_pins_b: sdmmc3-b4-od-1 {
		pins1 {
			pinmux = <STM32_PINMUX('B', 14, AF10)>, /* SDMMC3_D0 */
				 <STM32_PINMUX('D', 13, AF10)>, /* SDMMC3_D1 */
				 <STM32_PINMUX('B', 12, AF10)>, /* SDMMC3_D2 */
				 <STM32_PINMUX('D', 14, AF10)>; /* SDMMC3_D3 */
			slew-rate = <2>;
			drive-push-pull;
			bias-disable;
		};
		pins2 {
			pinmux = <STM32_PINMUX('B', 13, AF10)>; /* SDMMC3_CK */
			slew-rate = <3>;
			drive-push-pull;
			bias-disable;
		};
		pins3 {
			pinmux = <STM32_PINMUX('D', 12, AF10)>; /* SDMMC3_CMD */
			slew-rate = <2>;
			drive-open-drain;
			bias-disable;
		};
	};

	/omit-if-no-ref/
	sdmmc3_b4_sleep_pins_b: sdmmc3-b4-sleep-1 {
		pins {
			pinmux = <STM32_PINMUX('B', 14, ANALOG)>, /* SDMMC3_D0 */
				 <STM32_PINMUX('D', 13, ANALOG)>, /* SDMMC3_D1 */
				 <STM32_PINMUX('B', 12, ANALOG)>, /* SDMMC3_D2 */
				 <STM32_PINMUX('D', 14, ANALOG)>, /* SDMMC3_D3 */
				 <STM32_PINMUX('B', 13, ANALOG)>, /* SDMMC3_CK */
				 <STM32_PINMUX('D', 12, ANALOG)>; /* SDMMC3_CMD */
		};
	};

	/omit-if-no-ref/
	sdmmc2_d47_pins_b: sdmmc2-d47-1 {
		pins {
			pinmux = <STM32_PINMUX('E', 10, AF12)>, /* SDMMC2_D4 */
				 <STM32_PINMUX('E', 9, AF12)>, /* SDMMC2_D5 */
				 <STM32_PINMUX('E', 6, AF12)>, /* SDMMC2_D6 */
				 <STM32_PINMUX('E', 7, AF12)>; /* SDMMC2_D7 */
			slew-rate = <2>;
			drive-push-pull;
			bias-pull-up;
		};
	};

	/omit-if-no-ref/
	spi1_pins_a: spi1-0 {
		pins1 {
			pinmux = <STM32_PINMUX('G', 6, AF3)>, /* SPI1_SCK */
				 <STM32_PINMUX('I', 5, AF3)>; /* SPI1_MOSI */
			drive-push-pull;
			bias-disable;
			slew-rate = <1>;
		};
		pins2 {
			pinmux = <STM32_PINMUX('F', 12, AF3)>; /* SPI1_MISO */
			bias-disable;
		};
	};

	/omit-if-no-ref/
	spi1_sleep_pins_a: spi1-sleep-0 {
		pins1 {
			pinmux = <STM32_PINMUX('G', 6, ANALOG)>, /* SPI1_SCK */
				 <STM32_PINMUX('I', 5, ANALOG)>, /* SPI1_MOSI */
				 <STM32_PINMUX('F', 12, ANALOG)>; /* SPI1_MISO */
		};
	};

	/omit-if-no-ref/
	spi1_pins_b: spi1-1 {
		pins1 {
			pinmux = <STM32_PINMUX('G', 6, AF3)>, /* SPI1_SCK */
				 <STM32_PINMUX('H', 7, AF2)>; /* SPI1_MOSI */
			drive-push-pull;
			bias-disable;
			slew-rate = <1>;
		};
		pins2 {
			pinmux = <STM32_PINMUX('H', 8, AF2)>; /* SPI1_MISO */
			bias-disable;
		};
	};

	/omit-if-no-ref/
	spi1_sleep_pins_b: spi1-sleep-1 {
		pins1 {
			pinmux = <STM32_PINMUX('G', 6, ANALOG)>, /* SPI1_SCK */
				 <STM32_PINMUX('H', 7, ANALOG)>, /* SPI1_MOSI */
				 <STM32_PINMUX('H', 8, ANALOG)>; /* SPI1_MISO */
		};
	};

	/omit-if-no-ref/
	spi3_pins_a: spi3-0 {
		pins1 {
			pinmux = <STM32_PINMUX('B', 7, AF1)>, /* SPI3_SCK */
				 <STM32_PINMUX('B', 8, AF1)>; /* SPI3_MOSI */
			drive-push-pull;
			bias-disable;
			slew-rate = <1>;
		};
		pins2 {
			pinmux = <STM32_PINMUX('B', 10, AF1)>; /* SPI3_MISO */
			bias-disable;
		};
	};

	/omit-if-no-ref/
	spi3_sleep_pins_a: spi3-sleep-0 {
		pins1 {
			pinmux = <STM32_PINMUX('B', 7, ANALOG)>, /* SPI3_SCK */
				 <STM32_PINMUX('B', 8, ANALOG)>, /* SPI3_MOSI */
				 <STM32_PINMUX('B', 10, ANALOG)>; /* SPI3_MISO */
		};
	};

	/omit-if-no-ref/
	tim10_counter_pins_a: tim10-counter-0 {
		pins {
			pinmux = <STM32_PINMUX('B', 9, AF9)>; /* TIM10_CH1 */
			bias-disable;
		};
	};

	/omit-if-no-ref/
	tim10_counter_sleep_pins_a: tim10-counter-sleep-0 {
		pins {
			pinmux = <STM32_PINMUX('B', 9, ANALOG)>; /* TIM10_CH1 */
			bias-disable;
		};
	};

	/omit-if-no-ref/
	usart1_pins_b: usart1-1 {
		pins1 {
			pinmux = <STM32_PINMUX('B', 8, AF6)>; /* USART1_TX */
			bias-disable;
			drive-push-pull;
			slew-rate = <0>;
		};
		pins2 {
			pinmux = <STM32_PINMUX('B', 10, AF6)>; /* USART1_RX */
			bias-disable;
		};
	};

	/omit-if-no-ref/
	usart1_idle_pins_b: usart1-idle-1 {
		pins1 {
			pinmux = <STM32_PINMUX('B', 8, ANALOG)>; /* USART1_TX */
		};
		pins2 {
			pinmux = <STM32_PINMUX('B', 10, AF6)>; /* USART1_RX */
			bias-disable;
		};
	};

	/omit-if-no-ref/
	usart1_sleep_pins_b: usart1-sleep-1 {
		pins {
			pinmux = <STM32_PINMUX('B', 8, ANALOG)>, /* USART1_TX */
				 <STM32_PINMUX('B', 10, ANALOG)>; /* USART1_RX */
		};
	};

	/omit-if-no-ref/
	usart1_pins_a: usart1-0 {
		pins1 {
			pinmux = <STM32_PINMUX('A', 3, AF6)>, /* USART1_TX */
				 <STM32_PINMUX('A', 1, AF5)>;  /* USART1_RTS */
			bias-disable;
			drive-push-pull;
			slew-rate = <0>;
		};
		pins2 {
			pinmux = <STM32_PINMUX('A', 2, AF6)>, /* USART1_RX */
				 <STM32_PINMUX('A', 7, AF6)>; /* USART1_CTS_NSS */
			bias-pull-up;
		};
	};

	/omit-if-no-ref/
	usart1_idle_pins_a: usart1-idle-0 {
		pins1 {
			pinmux = <STM32_PINMUX('A', 3, ANALOG)>, /* USART1_TX */
				 <STM32_PINMUX('A', 7, ANALOG)>; /* USART1_CTS_NSS */
		};
		pins2 {
			pinmux = <STM32_PINMUX('A', 1, AF5)>; /* USART1_RTS */
			bias-disable;
			drive-push-pull;
			slew-rate = <0>;
		};
		pins3 {
			pinmux = <STM32_PINMUX('A', 2, AF6)>; /* USART1_RX */
			bias-pull-up;
		};
	};

	/omit-if-no-ref/
	usart1_sleep_pins_a: usart1-sleep-0 {
		pins {
			pinmux = <STM32_PINMUX('A', 3, ANALOG)>, /* USART1_TX */
				 <STM32_PINMUX('A', 1, ANALOG)>,  /* USART1_RTS */
				 <STM32_PINMUX('A', 7, ANALOG)>, /* USART1_CTS_NSS */
				 <STM32_PINMUX('A', 2, ANALOG)>; /* USART1_RX */
		};
	};

	/omit-if-no-ref/
	usart2_pins_a: usart2-0 {
		pins1 {
			pinmux = <STM32_PINMUX('A', 4, AF6)>; /* USART2_TX */
			bias-disable;
			drive-push-pull;
			slew-rate = <0>;
		};
		pins2 {
			pinmux = <STM32_PINMUX('A', 8, AF8)>; /* USART2_RX */
			bias-disable;
		};
	};

	/omit-if-no-ref/
	usart2_idle_pins_a: usart2-idle-0 {
		pins1 {
			pinmux = <STM32_PINMUX('A', 4, ANALOG)>; /* USART2_TX */
		};
		pins2 {
			pinmux = <STM32_PINMUX('A', 8, AF8)>; /* USART2_RX */
			bias-disable;
		};
	};

	/omit-if-no-ref/
	usart2_sleep_pins_a: usart2-sleep-0 {
		pins {
			pinmux = <STM32_PINMUX('A', 4, ANALOG)>, /* USART2_TX */
				 <STM32_PINMUX('A', 8, ANALOG)>; /* USART2_RX */
		};
	};

	/omit-if-no-ref/
	usart2_pins_b: usart2-1 {
		pins1 {
			pinmux = <STM32_PINMUX('A', 4, AF6)>, /* USART2_TX */
				 <STM32_PINMUX('A', 5, AF6)>; /* USART2_RTS */
			bias-disable;
			drive-push-pull;
			slew-rate = <0>;
		};
		pins2 {
			pinmux = <STM32_PINMUX('A', 8, AF8)>, /* USART2_RX */
				 <STM32_PINMUX('A', 9, AF6)>; /* USART2_CTS_NSS */
			bias-disable;
		};
	};

	/omit-if-no-ref/
	usart2_idle_pins_b: usart2-idle-1 {
		pins1 {
			pinmux = <STM32_PINMUX('A', 4, ANALOG)>, /* USART2_TX */
				 <STM32_PINMUX('A', 9, ANALOG)>; /* USART2_CTS_NSS */
		};
		pins2 {
			pinmux = <STM32_PINMUX('A', 5, AF6)>; /* USART2_RTS */
			bias-disable;
			drive-push-pull;
			slew-rate = <0>;
		};
		pins3 {
			pinmux = <STM32_PINMUX('A', 8, AF8)>; /* USART2_RX */
			bias-pull-up;
		};
	};

	/omit-if-no-ref/
	usart2_sleep_pins_b: usart2-sleep-1 {
		pins {
			pinmux = <STM32_PINMUX('A', 4, ANALOG)>, /* USART2_TX */
				 <STM32_PINMUX('A', 5, ANALOG)>, /* USART2_RTS */
				 <STM32_PINMUX('A', 9, ANALOG)>, /* USART2_CTS_NSS */
				 <STM32_PINMUX('A', 8, ANALOG)>; /* USART2_RX */
		};
	};

	/omit-if-no-ref/
	usart6_pins_a: usart6-0 {
		pins1 {
			pinmux = <STM32_PINMUX('F', 13, AF3)>, /* USART6_TX */
				 <STM32_PINMUX('G', 5, AF3)>;  /* USART6_RTS */
			bias-disable;
			drive-push-pull;
			slew-rate = <0>;
		};
		pins2 {
			pinmux = <STM32_PINMUX('F', 14, AF3)>, /* USART6_RX */
				 <STM32_PINMUX('F', 15, AF3)>; /* USART6_CTS_NSS */
			bias-pull-up;
		};
	};

	/omit-if-no-ref/
	usart6_idle_pins_a: usart6-idle-0 {
		pins1 {
			pinmux = <STM32_PINMUX('F', 13, ANALOG)>, /* USART6_TX */
				 <STM32_PINMUX('F', 15, ANALOG)>; /* USART6_CTS_NSS */
		};
		pins2 {
			pinmux = <STM32_PINMUX('G', 5, AF3)>; /* USART6_RTS */
			bias-disable;
			drive-push-pull;
			slew-rate = <0>;
		};
		pins3 {
			pinmux = <STM32_PINMUX('F', 14, AF3)>; /* USART6_RX */
			bias-pull-up;
		};
	};

	/omit-if-no-ref/
	usart6_sleep_pins_a: usart6-sleep-0 {
		pins {
			pinmux = <STM32_PINMUX('F', 13, ANALOG)>, /* USART6_TX */
				 <STM32_PINMUX('G', 5, ANALOG)>,  /* USART6_RTS */
				 <STM32_PINMUX('F', 15, ANALOG)>, /* USART6_CTS_NSS */
				 <STM32_PINMUX('F', 14, ANALOG)>; /* USART6_RX */
		};
	};

	/omit-if-no-ref/
	usart6_pins_b: usart6-1 {
		pins1 {
			pinmux = <STM32_PINMUX('F', 5, AF6)>; /* USART6_TX */
			bias-disable;
			drive-push-pull;
			slew-rate = <0>;
		};
		pins2 {
			pinmux = <STM32_PINMUX('F', 4, AF6)>; /* USART6_RX */
			bias-disable;
		};
	};

	/omit-if-no-ref/
	usart6_idle_pins_b: usart6-idle-1 {
		pins1 {
			pinmux = <STM32_PINMUX('F', 5, ANALOG)>; /* USART6_TX */
		};
		pins2 {
			pinmux = <STM32_PINMUX('F', 4, AF6)>; /* USART6_RX */
			bias-disable;
		};
	};

	/omit-if-no-ref/
	usart6_sleep_pins_b: usart6-sleep-1 {
		pins {
			pinmux = <STM32_PINMUX('F', 5, ANALOG)>, /* USART6_TX */
				 <STM32_PINMUX('F', 4, ANALOG)>; /* USART6_RX */
		};
	};

	/omit-if-no-ref/
	uart8_pins_a: uart8-0 {
		pins1 {
			pinmux = <STM32_PINMUX('I', 11, AF5)>, /* UART8_TX */
				 <STM32_PINMUX('B', 15, AF3)>;  /* UART8_RTS */
			bias-disable;
			drive-push-pull;
			slew-rate = <0>;
		};
		pins2 {
			pinmux = <STM32_PINMUX('F', 11, AF6)>, /* UART8_RX */
				 <STM32_PINMUX('H', 5, AF6)>; /* UART8_CTS_NSS */
			bias-pull-up;
		};
	};

	/omit-if-no-ref/
	uart8_idle_pins_a: uart8-idle-0 {
		pins1 {
			pinmux = <STM32_PINMUX('I', 11, ANALOG)>, /* UART8_TX */
				 <STM32_PINMUX('H', 5, ANALOG)>; /* UART8_CTS_NSS */
		};
		pins2 {
			pinmux = <STM32_PINMUX('B', 15, AF3)>; /* UART8_RTS */
			bias-disable;
			drive-push-pull;
			slew-rate = <0>;
		};
		pins3 {
			pinmux = <STM32_PINMUX('F', 11, AF6)>; /* UART8_RX */
			bias-pull-up;
		};
	};

	/omit-if-no-ref/
	uart8_sleep_pins_a: uart8-sleep-0 {
		pins {
			pinmux = <STM32_PINMUX('I', 11, ANALOG)>, /* UART8_TX */
				 <STM32_PINMUX('B', 15, ANALOG)>,  /* UART8_RTS */
				 <STM32_PINMUX('H', 5, ANALOG)>, /* UART8_CTS_NSS */
				 <STM32_PINMUX('F', 11, ANALOG)>; /* UART8_RX */
		};
	};

	/omit-if-no-ref/
	uart9_pins_a: uart9-0 {
		pins1 {
			pinmux = <STM32_PINMUX('G', 8, AF6)>, /* UART9_TX */
				 <STM32_PINMUX('F', 12, AF6)>;  /* UART9_RTS */
			bias-disable;
			drive-push-pull;
			slew-rate = <0>;
		};
		pins2 {
			pinmux = <STM32_PINMUX('I', 5, AF6)>, /* UART9_RX */
				 <STM32_PINMUX('G', 7, AF6)>; /* UART9_CTS_NSS */
			bias-pull-up;
		};
	};

	/omit-if-no-ref/
	uart9_idle_pins_a: uart9-idle-0 {
		pins1 {
			pinmux = <STM32_PINMUX('G', 8, ANALOG)>, /* UART9_TX */
				 <STM32_PINMUX('G', 7, ANALOG)>; /* UART9_CTS_NSS */
		};
		pins2 {
			pinmux = <STM32_PINMUX('F', 12, AF6)>; /* UART9_RTS */
			bias-disable;
			drive-push-pull;
			slew-rate = <0>;
		};
		pins3 {
			pinmux = <STM32_PINMUX('I', 5, AF6)>; /* UART9_RX */
			bias-pull-up;
		};
	};

	/omit-if-no-ref/
	uart9_sleep_pins_a: uart9-sleep-0 {
		pins {
			pinmux = <STM32_PINMUX('G', 8, ANALOG)>, /* UART9_TX */
				 <STM32_PINMUX('F', 12, ANALOG)>,  /* UART9_RTS */
				 <STM32_PINMUX('G', 7, ANALOG)>, /* UART9_CTS_NSS */
				 <STM32_PINMUX('I', 5, ANALOG)>; /* UART9_RX */
		};
	};
};

&pinctrl_z {
	/omit-if-no-ref/
	i2c8_pins_a: i2c8-0 {
		pins {
			pinmux = <STM32_PINMUX('Z', 4, AF8)>, /* I2C8_SCL */
				 <STM32_PINMUX('Z', 3, AF8)>; /* I2C8_SDA */
			bias-disable;
			drive-open-drain;
			slew-rate = <0>;
		};
	};

	/omit-if-no-ref/
	i2c8_sleep_pins_a: i2c8-sleep-0 {
		pins {
			pinmux = <STM32_PINMUX('Z', 4, ANALOG)>, /* I2C8_SCL */
				 <STM32_PINMUX('Z', 3, ANALOG)>; /* I2C8_SDA */
		};
	};

	/omit-if-no-ref/
	i2c8_pins_b: i2c8-1 {
		pins {
			pinmux = <STM32_PINMUX('Z', 4, AF8)>, /* I2C1_SCL */
				 <STM32_PINMUX('Z', 9, AF8)>; /* I2C1_SDA */
			bias-disable;
			drive-open-drain;
			slew-rate = <0>;
		};
	};

	/omit-if-no-ref/
	i2c8_sleep_pins_b: i2c8-sleep-1 {
		pins {
			pinmux = <STM32_PINMUX('Z', 4, ANALOG)>, /* I2C1_SCL */
				 <STM32_PINMUX('Z', 9, ANALOG)>; /* I2C1_SDA */
		};
	};

	/omit-if-no-ref/
	spi8_pins_a: spi8-0 {
		pins1 {
			pinmux = <STM32_PINMUX('Z', 2, AF3)>, /* SPI8_SCK */
				 <STM32_PINMUX('Z', 0, AF3)>; /* SPI8_MOSI */
			drive-push-pull;
			bias-disable;
			slew-rate = <1>;
		};
		pins2 {
			pinmux = <STM32_PINMUX('Z', 1, AF3)>; /* SPI8_MISO */
			bias-disable;
		};
	};

	/omit-if-no-ref/
	spi8_sleep_pins_a: spi8-sleep-0 {
		pins1 {
			pinmux = <STM32_PINMUX('Z', 2, ANALOG)>, /* SPI8_SCK */
				 <STM32_PINMUX('Z', 0, ANALOG)>, /* SPI8_MOSI */
				 <STM32_PINMUX('Z', 1, ANALOG)>; /* SPI8_MISO */
		};
	};

	/omit-if-no-ref/
	spi8_pins_b: spi8-1 {
		pins1 {
			pinmux = <STM32_PINMUX('Z', 5, AF3)>, /* SPI8_SCK */
				 <STM32_PINMUX('Z', 7, AF3)>; /* SPI8_MOSI */
			drive-push-pull;
			bias-disable;
			slew-rate = <1>;
		};
		pins2 {
			pinmux = <STM32_PINMUX('Z', 8, AF3)>; /* SPI8_MISO */
			bias-disable;
		};
	};

	/omit-if-no-ref/
	spi8_sleep_pins_b: spi8-sleep-1 {
		pins1 {
			pinmux = <STM32_PINMUX('Z', 5, ANALOG)>, /* SPI8_SCK */
				 <STM32_PINMUX('Z', 7, ANALOG)>, /* SPI8_MOSI */
				 <STM32_PINMUX('Z', 8, ANALOG)>; /* SPI8_MISO */
		};
	};
};
